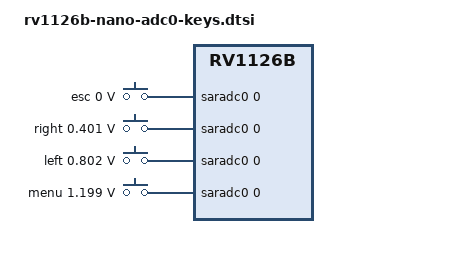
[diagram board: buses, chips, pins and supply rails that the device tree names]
// SPDX-License-Identifier: (GPL-2.0+ OR MIT)
/*
 * Copyright (c) 2025 Guangzhou EASY EAI Technology Co., Ltd.
 */

#include <dt-bindings/input/input.h>

/ {
	adc-keys {
		compatible = "adc-keys";
		io-channels = <&saradc0 0>;
		io-channel-names = "buttons";
		poll-interval = <100>;
		keyup-threshold-microvolt = <1800000>;

		esc-key {
			label = "esc";
			linux,code = <KEY_ESC>;
			press-threshold-microvolt = <0>;
		};

		right-key {
			label = "right";
			linux,code = <KEY_RIGHT>;
			press-threshold-microvolt = <400781>;
		};

		left-key {
			label = "left";
			linux,code = <KEY_LEFT>;
			press-threshold-microvolt = <801562>;
		};

		menu-key {
			label = "menu";
			linux,code = <KEY_MENU>;
			press-threshold-microvolt = <1198828>;
		};
	};
};
